# PIC32MX274F256D device description
Architecture: MIPS; Family: PIC32MX; Series: PIC32MX
Registers are 32-bit, read-write, no defined reset value unless marked. A register's access mark holds for its fields unless they carry their own. Offsets are from the block's base; [hi:lo] are bit positions; {n}, {i} and the like mark numbered series; 'fields as' and 'values as' point back to an identical list.

## FUSECONFIG
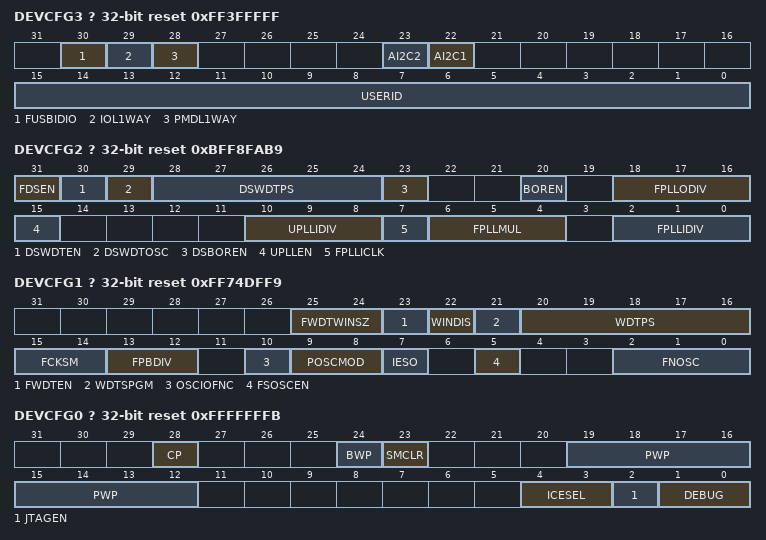
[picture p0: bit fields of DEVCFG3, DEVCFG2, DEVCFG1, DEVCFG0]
? DEVCFG3 size not given access not given reset 0xFF3FFFFF — Device Configuration Word 3
  [30] FUSBIDIO — USB USBID Selection bit
    1=ON (USBID pin is controlled by the USB module); 0=OFF (USBID pin is controlled by the port function)
  [29] IOL1WAY — Peripheral Pin Select Configuration bit
    1=ON (Allow only one reconfiguration); 0=OFF (Allow multiple reconfigurations)
  [28] PMDL1WAY — Peripheral Module Disable Configuration bit
    values as IOL1WAY
  [23] AI2C2 — Alternate I/O Select for I2C2 bit
    1=ON (I2C2 uses the ASDA2/ASCL2 pins); 0=OFF (I2C2 uses the SDA2/SCL2 pins)
  [22] AI2C1 — Alternate I/O Select for I2C1 bit
    1=ON (I2C1 uses the ASDA1/ASCL1 pins); 0=OFF (I2C1 uses the SDA1/SCL1 pins)
  [15:0] USERID
    ?=User ID
? DEVCFG2 size not given access not given reset 0xBFF8FAB9 — Device Configuration Word 2
  [31] FDSEN — Deep Sleep Enable bit
    0=OFF (Sleep mode is entered on a WAIT command); 1=ON (Deep Sleep mode is entered on a WAIT command)
  [30] DSWDTEN — Deep Sleep Watchdog Timer Enable bit
    0=OFF (Disable DSWDT during Deep Sleep Mode); 1=ON (Enable DSWDT during Deep Sleep Mode)
  [29] DSWDTOSC — Deep Sleep Watchdog Timer Reference Clock Select bit
    0=SOSC (Select SOSC as DSWDT Reference Clock); 1=LPRC (Select LPRC as DSWDT Reference clock)
  [28:24] DSWDTPS — Deep Sleep Watchdog Timer Postscale Select bits
    {v}=DSPS{v+1} (1:2^{v+5}) (v=0..31)
  [23] DSBOREN — Deep Sleep BOR Enable bit
    0=OFF (Disable BOR during Deep Sleep mode, but remains enabled in other sleep modes); 1=ON (Enable BOR during Deep Sleep mode)
  [20] BOREN — Brown-Out Reset (BOR) Enable bit
    0=OFF (Disable BOR); 1=ON (Enable BOR in all modes except Deep Sleep mode)
  [18:16] FPLLODIV — Default PLL Output Divisor bits
    0=DIV_1 (PLL Divide by 1); 1=DIV_2 (PLL Divide by 2); 2=DIV_4 (PLL Divide by 4); 3=DIV_8 (PLL Divide by 8); 4=DIV_16 (PLL Divide by 16); 5=DIV_32 (PLL Divide by 32); 6=DIV_64 (PLL Divide by 64); 7=DIV_256 (PLL Divide by 256)
  [15] UPLLEN — USB PLL Enable bit
    0=ON (Enable USB PLL); 1=OFF (Disable and bypass USB PLL)
  [10:8] UPLLIDIV — USB PLL Input Divider bits
    {v}=DIV_{v+1} ({v+1}x divider) (v=0..5); 6=DIV_10 (10x divider); 7=DIV_12 (12x divider)
  [7] FPLLICLK — System PLL Input Clock Select bit
    0=PLL_POSC (POSC is input to the System PLL); 1=PLL_FRC (FRC is input to the System PLL)
  [6:4] FPLLMUL — PLL Multiplier bits
    {v}=MUL_{v+15} ({v+15}x Multiplier) (v=0..6); 7=MUL_24 (24x Multiplier)
  [2:0] FPLLIDIV — PLL Input Divider bits
    {v}=DIV_{v+1} ({v+1}x Divider) (v=0..5); 6=DIV_10 (10x Divider); 7=DIV_12 (12x Divider)
? DEVCFG1 size not given access not given reset 0xFF74DFF9 — Device Configuration Word 1
  [25:24] FWDTWINSZ — Watchdog Timer Window Size bits
    0=WINSZ_75 (Window Size is 75%); 1=WINSZ_50 (Window Size is 50%); 2=WINSZ_37 (Window Size is 37.5%); 3=WINSZ_25 (Window Size is 25%)
  [23] FWDTEN — Watchdog Timer Enable bit
    0=OFF (WDT Disabled (SWDTEN Bit Controls)); 1=ON (WDT Enabled)
  [22] WINDIS — Watchdog Timer Window Enable bit
    0=ON (Watchdog Timer is in Window Mode); 1=OFF (Watchdog Timer is in Non-Window Mode)
  [21] WDTSPGM — Watchdog Timer Stop During Flash Programming bit
    1=ON (Watchdog Timer stops during Flash programming); 0=OFF (Watchdog Timer runs during Flash programming)
  [20:16] WDTPS — Watchdog Timer Postscale Select bits
    0=PS1 (1:1); 1=PS2 (1:2); 2=PS4 (1:4); 3=PS8 (1:8); 4=PS16 (1:16); 5=PS32 (1:32); 6=PS64 (1:64); 7=PS128 (1:128); 8=PS256 (1:256); 9=PS512 (1:512); 10=PS1024 (1:1024); 11=PS2048 (1:2048); 12=PS4096 (1:4096); 13=PS8192 (1:8192); 14=PS16384 (1:16384); 15=PS32768 (1:32768); 16=PS65536 (1:65536); 17=PS131072 (1:131072); 18=PS262144 (1:262144); 19=PS524288 (1:524288); 20=PS1048576 (1:1048576)
  [15:14] FCKSM — Clock Switching and Monitor Selection Configuration bits
    0=CSECME (Clock Switch Enable, FSCM Enabled); 1=CSECMD (Clock Switch Enable, FSCM Disabled); 3=CSDCMD (Clock Switch Disable, FSCM Disabled)
  [13:12] FPBDIV — Peripheral Bus Clock Divisor Default Value bits
    0=DIV_1 (Pb_Clk is Sys_Clk/1); 1=DIV_2 (Pb_Clk is Sys_Clk/2); 2=DIV_4 (Pb_Clk is Sys_Clk/4); 3=DIV_8 (Pb_Clk is Sys_Clk/8)
  [10] OSCIOFNC — CLKO Enable Configuration bit
    1=OFF (Disabled); 0=ON (Enabled)
  [9:8] POSCMOD — Primary Oscillator Configuration bits
    0=EC (External clock mode); 1=XT (XT osc mode); 2=HS (HS osc mode); 3=OFF (Primary osc disabled)
  [7] IESO — Internal External Switchover bit
    0=OFF (Internal External Switchover mode is disabled (Two-Speed Start-up is disabled)); 1=ON (Internal External Switchover mode is enabled (Two-Speed Start-up is enabled))
  [5] FSOSCEN — Secondary Oscillator Enable bit
    0=OFF (Disable Secondary Oscillator); 1=ON (Enable Secondary Oscillator)
  [2:0] FNOSC — Oscillator Selection bits
    0=FRC (Fast RC Osc (FRC)); 1=SPLL (System PLL); 2=POSC (Primary Osc (HS,EC, XT)); 4=SOSC (Low Power Secondary Osc (SOSC)); 5=LPRC (Low Power RC Osc (LPRC))
? DEVCFG0 size not given access not given reset 0xFFFFFFFB — Device Configuration Word 0
  [28] CP — Code-Protect bit
    0=ON (Protection Enabled); 1=OFF (Protection Disabled)
  [24] BWP — Boot Flash Write-Protect bit
    0=ON (Protection Enabled); 1=OFF (Protection Disabled)
  [23] SMCLR — Soft Master Clear Enable bit
    0=MCLR_POR (MCLR pin generates an emulated POR Reset); 1=MCLR_NORM (MCLR pin generates a normal system Reset)
  [19:12] PWP — Program Flash Write-Protect bits
    255=OFF (Disable); 254=PWP4K (First 4K); 253=PWP8K (First 8K); 252=PWP12K (First 12K); 251=PWP16K (First 16K); 250=PWP20K (First 20K); 249=PWP24K (First 24K); 248=PWP28K (First 28K); 247=PWP32K (First 32K); 246=PWP36K (First 36K); 245=PWP40K (First 40K); 244=PWP44K (First 44K); 243=PWP48K (First 48K); 242=PWP52K (First 52K); 241=PWP56K (First 56K); 240=PWP60K (First 60K); 239=PWP64K (First 64K); 238=PWP68K (First 68K); 237=PWP72K (First 72K); 236=PWP76K (First 76K); 235=PWP80K (First 80K); 234=PWP84K (First 84K); 233=PWP88K (First 88K); 232=PWP92K (First 92K); 231=PWP96K (First 96K); 230=PWP100K (First 100K); 229=PWP104K (First 104K); 228=PWP108K (First 108K); 227=PWP112K (First 112K); 226=PWP116K (First 116K); 225=PWP120K (First 120K); 224=PWP124K (First 124K); 223=PWP128K (First 128K); 222=PWP132K (First 132K); 221=PWP136K (First 136K); 220=PWP140K (First 140K); 219=PWP144K (First 144K); 218=PWP148K (First 148K); 217=PWP152K (First 152K); 216=PWP156K (First 156K); 215=PWP160K (First 160K); 214=PWP164K (First 164K); 213=PWP168K (First 168K); 212=PWP172K (First 172K); 211=PWP176K (First 176K); 210=PWP180K (First 180K); 209=PWP184K (First 184K); 208=PWP188K (First 188K); 207=PWP192K (First 192K); 206=PWP196K (First 196K); 205=PWP200K (First 200K); 204=PWP204K (First 204K); 203=PWP208K (First 208K); 202=PWP212K (First 212K); 201=PWP216K (First 216K); 200=PWP220K (First 220K); 199=PWP224K (First 224K); 198=PWP228K (First 228K); 197=PWP232K (First 232K); 196=PWP236K (First 236K); 195=PWP240K (First 240K); 194=PWP244K (First 244K); 193=PWP248K (First 248K); 192=PWP252K (First 252K); 191=PWP256K (First 256K)
  [4:3] ICESEL — In-Circuit Emulator/Debugger Communication Channel Select bits
    3=ICS_PGx1 (Communicate on PGEC1/PGED1); 2=ICS_PGx2 (Communicate on PGEC2/PGED2); 1=ICS_PGx3 (Communicate on PGEC3/PGED3); 0=ICS_PGx4 (Communicate on PGEC4/PGED4)
  [2] JTAGEN — JTAG Enable bit
    1=ON (JTAG Port Enabled); 0=OFF (JTAG Disabled)
  [1:0] DEBUG — Background Debugger Enable bits (forced to 11 if code-protect is enabled)
    0=ON (Debugger is Enabled); 3=OFF (Debugger is Disabled)

## Notices in the file
Copyright (c) 2019 Microchip Technology Inc.
SPDX-License-Identifier: Apache-2.0
Licensed under the Apache License, Version 2.0 (the "License");
you may not use this file except in compliance with the License.
You may obtain a copy of the License at
http://www.apache.org/licenses/LICENSE-2.0
Unless required by applicable law or agreed to in writing, software
distributed under the License is distributed on an "AS IS" BASIS,
WITHOUT WARRANTIES OR CONDITIONS OF ANY KIND, either express or implied.
See the License for the specific language governing permissions and
limitations under the License.
